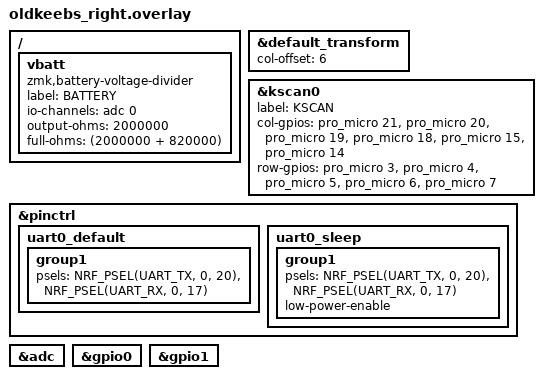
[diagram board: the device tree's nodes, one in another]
#include "oldkeebs.dtsi"

&default_transform {
    col-offset = <6>;
};

&kscan0 {
    label = "KSCAN";

    col-gpios
            = <&pro_micro 21 GPIO_ACTIVE_HIGH>
            , <&pro_micro 20 GPIO_ACTIVE_HIGH>
            , <&pro_micro 19 GPIO_ACTIVE_HIGH>
            , <&pro_micro 18 GPIO_ACTIVE_HIGH>
            , <&pro_micro 15 GPIO_ACTIVE_HIGH>
            , <&pro_micro 14 GPIO_ACTIVE_HIGH>
            ;

    row-gpios
        = <&pro_micro 3 (GPIO_ACTIVE_HIGH | GPIO_PULL_DOWN)>
        , <&pro_micro 4 (GPIO_ACTIVE_HIGH | GPIO_PULL_DOWN)>
        , <&pro_micro 5 (GPIO_ACTIVE_HIGH | GPIO_PULL_DOWN)>
        , <&pro_micro 6 (GPIO_ACTIVE_HIGH | GPIO_PULL_DOWN)>
        , <&pro_micro 7 (GPIO_ACTIVE_HIGH | GPIO_PULL_DOWN)>
        ;
};

&pinctrl {
    uart0_default: uart0_default {
        group1 {
            psels = <NRF_PSEL(UART_TX, 0, 20)>,
                    <NRF_PSEL(UART_RX, 0, 17)>;
        };
    };

    uart0_sleep: uart0_sleep {
        group1 {
            psels = <NRF_PSEL(UART_TX, 0, 20)>,
                    <NRF_PSEL(UART_RX, 0, 17)>;
            low-power-enable;
        };
    };
};

/ {
    vbatt: vbatt {
        compatible = "zmk,battery-voltage-divider";
        label = "BATTERY";
        io-channels = <&adc 0>;
        output-ohms = <2000000>;
        full-ohms = <(2000000 + 820000)>;
    };
};

&adc {
    status = "okay";
};

&gpio0 {
    status = "okay";
};

&gpio1 {
    status = "okay";
};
